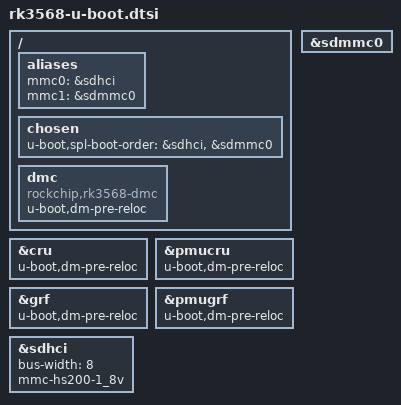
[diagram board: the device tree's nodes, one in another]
// SPDX-License-Identifier: (GPL-2.0+ OR MIT)
/*
 * (C) Copyright 2021 Rockchip Electronics Co., Ltd
 */

/ {
	aliases {
		mmc0 = &sdhci;
		mmc1 = &sdmmc0;
	};

	chosen {
		u-boot,spl-boot-order = &sdhci, &sdmmc0;
	};

	dmc: dmc {
		compatible = "rockchip,rk3568-dmc";
		u-boot,dm-pre-reloc;
		status = "okay";
	};
};

&cru {
	u-boot,dm-pre-reloc;
	status = "okay";
};

&pmucru {
	u-boot,dm-pre-reloc;
	status = "okay";
};

&grf {
	u-boot,dm-pre-reloc;
	status = "okay";
};

&pmugrf {
	u-boot,dm-pre-reloc;
	status = "okay";
};

&sdmmc0 {
	u-boot,dm-spl;
	status = "okay";
};

&sdhci {
	bus-width = <8>;
	u-boot,dm-spl;
	mmc-hs200-1_8v;
	status = "okay";
};

